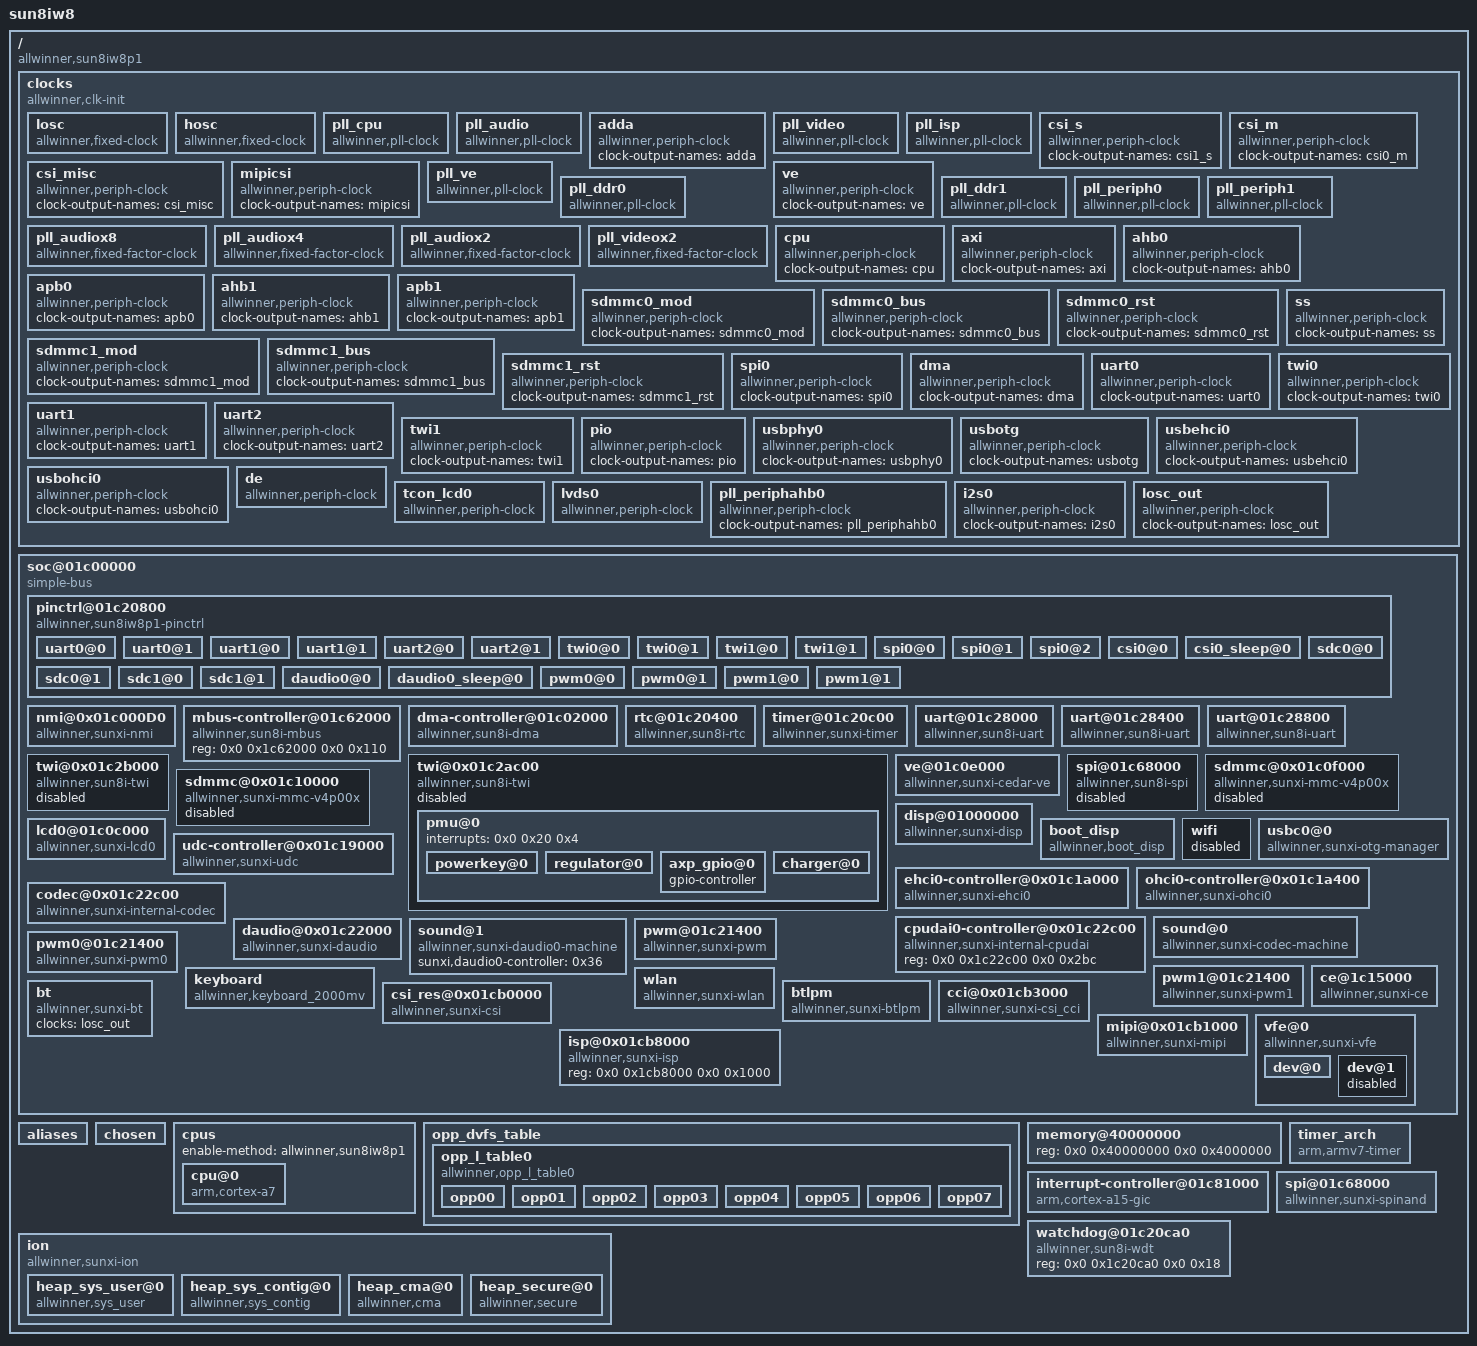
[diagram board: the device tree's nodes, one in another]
/dts-v1/;

/ {
	model = "sun8iw8";
	compatible = "allwinner,sun8iw8p1";
	interrupt-parent = <0x1>;
	#address-cells = <0x2>;
	#size-cells = <0x2>;

	clocks {
		compatible = "allwinner,clk-init";
		device_type = "clocks";
		#address-cells = <0x2>;
		#size-cells = <0x2>;
		ranges;
		reg = <0x0 0x1c20000 0x0 0x324 0x0 0x1c20460 0x0 0x4>;

		losc {
			#clock-cells = <0x0>;
			compatible = "allwinner,fixed-clock";
			clock-frequency = <0x8000>;
			clock-output-names = "losc";
		};

		hosc {
			#clock-cells = <0x0>;
			compatible = "allwinner,fixed-clock";
			clock-frequency = <0x16e3600>;
			clock-output-names = "hosc";
			linux,phandle = <0x1f>;
			phandle = <0x1f>;
		};

		pll_cpu {
			#clock-cells = <0x0>;
			compatible = "allwinner,pll-clock";
			lock-mode = "old";
			assigned-clock-rates = <0x1f78a400>;
			clock-output-names = "pll_cpu";
			linux,phandle = <0x43>;
			phandle = <0x43>;
		};

		pll_audio {
			#clock-cells = <0x0>;
			compatible = "allwinner,pll-clock";
			lock-mode = "old";
			clock-output-names = "pll_audio";
			linux,phandle = <0x2>;
			phandle = <0x2>;
		};

		adda {
			#clock-cells = <0x0>;
			compatible = "allwinner,periph-clock";
			clock-output-names = "adda";
			linux,phandle = <0x30>;
			phandle = <0x30>;
		};

		pll_video {
			#clock-cells = <0x0>;
			compatible = "allwinner,pll-clock";
			lock-mode = "old";
			assigned-clock-rates = <0x11b3dc40>;
			clock-output-names = "pll_video";
			linux,phandle = <0x3>;
			phandle = <0x3>;
		};

		pll_isp {
			#clock-cells = <0x0>;
			compatible = "allwinner,pll-clock";
			lock-mode = "old";
			clock-output-names = "pll_isp";
			linux,phandle = <0x41>;
			phandle = <0x41>;
		};

		csi_s {
			#clock-cells = <0x0>;
			compatible = "allwinner,periph-clock";
			clock-output-names = "csi1_s";
			linux,phandle = <0x3e>;
			phandle = <0x3e>;
		};

		csi_m {
			#clock-cells = <0x0>;
			compatible = "allwinner,periph-clock";
			clock-output-names = "csi0_m";
			linux,phandle = <0x3f>;
			phandle = <0x3f>;
		};

		csi_misc {
			#clock-cells = <0x0>;
			compatible = "allwinner,periph-clock";
			clock-output-names = "csi_misc";
			linux,phandle = <0x40>;
			phandle = <0x40>;
		};

		mipicsi {
			#clock-cells = <0x0>;
			compatible = "allwinner,periph-clock";
			clock-output-names = "mipicsi";
			linux,phandle = <0x42>;
			phandle = <0x42>;
		};

		pll_ve {
			#clock-cells = <0x0>;
			compatible = "allwinner,pll-clock";
			lock-mode = "old";
			clock-output-names = "pll_ve";
			linux,phandle = <0x19>;
			phandle = <0x19>;
		};

		ve {
			#clock-cells = <0x0>;
			compatible = "allwinner,periph-clock";
			clock-output-names = "ve";
			linux,phandle = <0x1a>;
			phandle = <0x1a>;
		};

		pll_ddr0 {
			#clock-cells = <0x0>;
			compatible = "allwinner,pll-clock";
			lock-mode = "old";
			assigned-clock-rates = <0x1298be00>;
			clock-output-names = "pll_ddr0";
		};

		pll_ddr1 {
			#clock-cells = <0x0>;
			compatible = "allwinner,pll-clock";
			lock-mode = "old";
			clock-output-names = "pll_ddr1";
		};

		pll_periph0 {
			#clock-cells = <0x0>;
			compatible = "allwinner,pll-clock";
			lock-mode = "old";
			clock-output-names = "pll_periph0";
			linux,phandle = <0x4>;
			phandle = <0x4>;
		};

		pll_periph1 {
			#clock-cells = <0x0>;
			compatible = "allwinner,pll-clock";
			lock-mode = "old";
			clock-output-names = "pll_periph1";
			linux,phandle = <0x20>;
			phandle = <0x20>;
		};

		pll_audiox8 {
			#clock-cells = <0x0>;
			compatible = "allwinner,fixed-factor-clock";
			clocks = <0x2>;
			clock-mult = <0x8>;
			clock-div = <0x1>;
			clock-output-names = "pll_audiox8";
		};

		pll_audiox4 {
			#clock-cells = <0x0>;
			compatible = "allwinner,fixed-factor-clock";
			clocks = <0x2>;
			clock-mult = <0x8>;
			clock-div = <0x2>;
			clock-output-names = "pll_audiox4";
		};

		pll_audiox2 {
			#clock-cells = <0x0>;
			compatible = "allwinner,fixed-factor-clock";
			clocks = <0x2>;
			clock-mult = <0x8>;
			clock-div = <0x4>;
			clock-output-names = "pll_audiox2";
		};

		pll_videox2 {
			#clock-cells = <0x0>;
			compatible = "allwinner,fixed-factor-clock";
			clocks = <0x3>;
			clock-mult = <0x2>;
			clock-div = <0x1>;
			clock-output-names = "pll_videox2";
		};

		cpu {
			#clock-cells = <0x0>;
			compatible = "allwinner,periph-clock";
			clock-output-names = "cpu";
		};

		axi {
			#clock-cells = <0x0>;
			compatible = "allwinner,periph-clock";
			clock-output-names = "axi";
		};

		ahb0 {
			#clock-cells = <0x0>;
			compatible = "allwinner,periph-clock";
			clock-output-names = "ahb0";
		};

		apb0 {
			#clock-cells = <0x0>;
			compatible = "allwinner,periph-clock";
			clock-output-names = "apb0";
		};

		ahb1 {
			#clock-cells = <0x0>;
			compatible = "allwinner,periph-clock";
			clock-output-names = "ahb1";
		};

		apb1 {
			#clock-cells = <0x0>;
			compatible = "allwinner,periph-clock";
			clock-output-names = "apb1";
		};

		sdmmc0_mod {
			#clock-cells = <0x0>;
			compatible = "allwinner,periph-clock";
			clock-output-names = "sdmmc0_mod";
			linux,phandle = <0x21>;
			phandle = <0x21>;
		};

		sdmmc0_bus {
			#clock-cells = <0x0>;
			compatible = "allwinner,periph-clock";
			clock-output-names = "sdmmc0_bus";
			linux,phandle = <0x22>;
			phandle = <0x22>;
		};

		sdmmc0_rst {
			#clock-cells = <0x0>;
			compatible = "allwinner,periph-clock";
			clock-output-names = "sdmmc0_rst";
			linux,phandle = <0x23>;
			phandle = <0x23>;
		};

		sdmmc1_mod {
			#clock-cells = <0x0>;
			compatible = "allwinner,periph-clock";
			clock-output-names = "sdmmc1_mod";
			linux,phandle = <0x27>;
			phandle = <0x27>;
		};

		sdmmc1_bus {
			#clock-cells = <0x0>;
			compatible = "allwinner,periph-clock";
			clock-output-names = "sdmmc1_bus";
			linux,phandle = <0x28>;
			phandle = <0x28>;
		};

		sdmmc1_rst {
			#clock-cells = <0x0>;
			compatible = "allwinner,periph-clock";
			clock-output-names = "sdmmc1_rst";
			linux,phandle = <0x29>;
			phandle = <0x29>;
		};

		ss {
			#clock-cells = <0x0>;
			compatible = "allwinner,periph-clock";
			clock-output-names = "ss";
			linux,phandle = <0x3d>;
			phandle = <0x3d>;
		};

		spi0 {
			#clock-cells = <0x0>;
			compatible = "allwinner,periph-clock";
			clock-output-names = "spi0";
			linux,phandle = <0x1b>;
			phandle = <0x1b>;
		};

		dma {
			#clock-cells = <0x0>;
			compatible = "allwinner,periph-clock";
			clock-output-names = "dma";
			linux,phandle = <0x9>;
			phandle = <0x9>;
		};

		uart0 {
			#clock-cells = <0x0>;
			compatible = "allwinner,periph-clock";
			clock-output-names = "uart0";
			linux,phandle = <0xa>;
			phandle = <0xa>;
		};

		uart1 {
			#clock-cells = <0x0>;
			compatible = "allwinner,periph-clock";
			clock-output-names = "uart1";
			linux,phandle = <0xd>;
			phandle = <0xd>;
		};

		uart2 {
			#clock-cells = <0x0>;
			compatible = "allwinner,periph-clock";
			clock-output-names = "uart2";
			linux,phandle = <0x10>;
			phandle = <0x10>;
		};

		twi0 {
			#clock-cells = <0x0>;
			compatible = "allwinner,periph-clock";
			clock-output-names = "twi0";
			linux,phandle = <0x13>;
			phandle = <0x13>;
		};

		twi1 {
			#clock-cells = <0x0>;
			compatible = "allwinner,periph-clock";
			clock-output-names = "twi1";
			linux,phandle = <0x16>;
			phandle = <0x16>;
		};

		pio {
			#clock-cells = <0x0>;
			compatible = "allwinner,periph-clock";
			clock-output-names = "pio";
			linux,phandle = <0x8>;
			phandle = <0x8>;
		};

		usbphy0 {
			#clock-cells = <0x0>;
			compatible = "allwinner,periph-clock";
			clock-output-names = "usbphy0";
			linux,phandle = <0x2c>;
			phandle = <0x2c>;
		};

		usbotg {
			#clock-cells = <0x0>;
			compatible = "allwinner,periph-clock";
			clock-output-names = "usbotg";
			linux,phandle = <0x2d>;
			phandle = <0x2d>;
		};

		usbehci0 {
			#clock-cells = <0x0>;
			compatible = "allwinner,periph-clock";
			clock-output-names = "usbehci0";
			linux,phandle = <0x2e>;
			phandle = <0x2e>;
		};

		usbohci0 {
			#clock-cells = <0x0>;
			compatible = "allwinner,periph-clock";
			clock-output-names = "usbohci0";
			linux,phandle = <0x2f>;
			phandle = <0x2f>;
		};

		de {
			#clock-cells = <0x0>;
			compatible = "allwinner,periph-clock";
			assigned-clock-parents = <0x4>;
			assigned-clock-rates = <0x11e1a300>;
			assigned-clocks = <0x5>;
			clock-output-names = "de";
			linux,phandle = <0x5>;
			phandle = <0x5>;
		};

		tcon_lcd0 {
			#clock-cells = <0x0>;
			compatible = "allwinner,periph-clock";
			assigned-clocks = <0x6>;
			clock-output-names = "tcon";
			linux,phandle = <0x6>;
			phandle = <0x6>;
		};

		lvds0 {
			#clock-cells = <0x0>;
			compatible = "allwinner,periph-clock";
			assigned-clocks = <0x7>;
			clock-output-names = "lvds";
			linux,phandle = <0x7>;
			phandle = <0x7>;
		};

		pll_periphahb0 {
			#clock-cells = <0x0>;
			compatible = "allwinner,periph-clock";
			clock-output-names = "pll_periphahb0";
		};

		i2s0 {
			#clock-cells = <0x0>;
			compatible = "allwinner,periph-clock";
			clock-output-names = "i2s0";
			linux,phandle = <0x33>;
			phandle = <0x33>;
		};

		losc_out {
			#clock-cells = <0x0>;
			compatible = "allwinner,periph-clock";
			clock-output-names = "losc_out";
		};
	};

	soc@01c00000 {
		compatible = "simple-bus";
		#address-cells = <0x2>;
		#size-cells = <0x2>;
		device_type = "soc";
		ranges;

		pinctrl@01c20800 {
			compatible = "allwinner,sun8iw8p1-pinctrl";
			reg = <0x0 0x1c20800 0x0 0x400>;
			device_type = "pio";
			clocks = <0x8>;
			gpio-controller;
			interrupt-controller;
			#interrupt-cells = <0x2>;
			#size-cells = <0x0>;
			#gpio-cells = <0x6>;
			interrupts = <0x0 0xf 0x4 0x0 0x11 0x4>;
			linux,phandle = <0x26>;
			phandle = <0x26>;

			uart0@0 {
				allwinner,pins = "PB8", "PB9";
				allwinner,pname = "uart0_tx", "uart0_rx";
				allwinner,function = "uart0";
				allwinner,muxsel = <0x3>;
				allwinner,drive = <0x1>;
				allwinner,pull = <0x1>;
				linux,phandle = <0xb>;
				phandle = <0xb>;
			};

			uart0@1 {
				allwinner,pins = "PB8", "PB9";
				allwinner,function = "io_disabled";
				allwinner,muxsel = <0x7>;
				allwinner,drive = <0x1>;
				allwinner,pull = <0x1>;
				linux,phandle = <0xc>;
				phandle = <0xc>;
			};

			uart1@0 {
				allwinner,pins = "PE21", "PE22";
				allwinner,pname = "uart1_tx", "uart1_rx";
				allwinner,function = "uart1";
				allwinner,muxsel = <0x4>;
				allwinner,drive = <0x1>;
				allwinner,pull = <0x1>;
				linux,phandle = <0xe>;
				phandle = <0xe>;
			};

			uart1@1 {
				allwinner,pins = "PE21", "PE22";
				allwinner,function = "io_disabled";
				allwinner,muxsel = <0x7>;
				allwinner,drive = <0x1>;
				allwinner,pull = <0x1>;
				linux,phandle = <0xf>;
				phandle = <0xf>;
			};

			uart2@0 {
				allwinner,pins = "PB0", "PB1";
				allwinner,pname = "uart2_tx", "uart2_rx";
				allwinner,function = "uart2";
				allwinner,muxsel = <0x2>;
				allwinner,drive = <0x1>;
				allwinner,pull = <0x1>;
				linux,phandle = <0x11>;
				phandle = <0x11>;
			};

			uart2@1 {
				allwinner,pins = "PB0", "PB1";
				allwinner,function = "io_disabled";
				allwinner,muxsel = <0x7>;
				allwinner,drive = <0x1>;
				allwinner,pull = <0x1>;
				linux,phandle = <0x12>;
				phandle = <0x12>;
			};

			twi0@0 {
				allwinner,pins = "PB6", "PB7";
				allwinner,pname = "twi0_scl", "twi0_sda";
				allwinner,function = "twi0";
				allwinner,muxsel = <0x2>;
				allwinner,drive = <0x1>;
				allwinner,pull = <0x0>;
				linux,phandle = <0x14>;
				phandle = <0x14>;
			};

			twi0@1 {
				allwinner,pins = "PB6", "PB7";
				allwinner,function = "io_disabled";
				allwinner,muxsel = <0x7>;
				allwinner,drive = <0x1>;
				allwinner,pull = <0x0>;
				linux,phandle = <0x15>;
				phandle = <0x15>;
			};

			twi1@0 {
				allwinner,pins = "PB8", "PB9";
				allwinner,pname = "twi1_scl", "twi1_sda";
				allwinner,function = "twi1";
				allwinner,muxsel = <0x2>;
				allwinner,drive = <0x1>;
				allwinner,pull = <0x0>;
				linux,phandle = <0x17>;
				phandle = <0x17>;
			};

			twi1@1 {
				allwinner,pins = "PB8", "PB9";
				allwinner,function = "io_disabled";
				allwinner,muxsel = <0x7>;
				allwinner,drive = <0x1>;
				allwinner,pull = <0x0>;
				linux,phandle = <0x18>;
				phandle = <0x18>;
			};

			spi0@0 {
				allwinner,pins = "PC3", "PC0", "PC1";
				allwinner,pname = "spi0_mosi", "spi0_miso", "spi0_sclk";
				allwinner,function = "spi0";
				allwinner,muxsel = <0x3>;
				allwinner,drive = <0x1>;
				allwinner,pull = <0x0>;
				linux,phandle = <0x1c>;
				phandle = <0x1c>;
			};

			spi0@1 {
				allwinner,pins = "PC2";
				allwinner,pname = "spi0_cs0";
				allwinner,function = "spi0";
				allwinner,muxsel = <0x3>;
				allwinner,drive = <0x1>;
				allwinner,pull = <0x1>;
				linux,phandle = <0x1d>;
				phandle = <0x1d>;
			};

			spi0@2 {
				allwinner,pins = "PC3", "PC0", "PC1", "PC2";
				allwinner,function = "io_disabled";
				allwinner,muxsel = <0x7>;
				allwinner,drive = <0x3>;
				allwinner,pull = <0x1>;
				linux,phandle = <0x1e>;
				phandle = <0x1e>;
			};

			csi0@0 {
				allwinner,pins = "PE21", "PE22";
				allwinner,pname = "csi0_sck", "csi0_sda";
				allwinner,function = "csi0";
				allwinner,muxsel = <0x3>;
				allwinner,drive = <0x1>;
				allwinner,pull = <0x0>;
			};

			csi0_sleep@0 {
				allwinner,pins = "PE21", "PE22";
				allwinner,pname = "csi0_sck", "csi0_sda";
				allwinner,function = "io_disabled";
				allwinner,muxsel = <0x7>;
				allwinner,drive = <0x1>;
				allwinner,pull = <0x0>;
			};

			sdc0@0 {
				allwinner,pins = "PF0", "PF1", "PF2", "PF3", "PF4", "PF5";
				allwinner,function = "sdc0";
				allwinner,muxsel = <0x2>;
				allwinner,drive = <0x1>;
				allwinner,pull = <0x1>;
				linux,phandle = <0x24>;
				phandle = <0x24>;
			};

			sdc0@1 {
				allwinner,pins = "PF0", "PF1", "PF2", "PF3", "PF4", "PF5";
				allwinner,function = "io_disabled";
				allwinner,muxsel = <0x7>;
				allwinner,drive = <0x1>;
				allwinner,pull = <0x1>;
				linux,phandle = <0x25>;
				phandle = <0x25>;
			};

			sdc1@0 {
				allwinner,pins = "PG0", "PG1", "PG2", "PG3", "PG4", "PG5";
				allwinner,function = "sdc1";
				allwinner,muxsel = <0x2>;
				allwinner,drive = <0x1>;
				allwinner,pull = <0x1>;
				linux,phandle = <0x2a>;
				phandle = <0x2a>;
			};

			sdc1@1 {
				allwinner,pins = "PG0", "PG1", "PG2", "PG3", "PG4", "PG5";
				allwinner,function = "io_disabled";
				allwinner,muxsel = <0x7>;
				allwinner,drive = <0x1>;
				allwinner,pull = <0x1>;
				linux,phandle = <0x2b>;
				phandle = <0x2b>;
			};

			daudio0@0 {
				allwinner,pins = "PG10", "PG11", "PG12";
				allwinner,function = "tdm0";
				allwinner,muxsel = <0x2>;
				allwinner,driver = <0x1>;
				allwinner,pull = <0x1>;
				linux,phandle = <0x34>;
				phandle = <0x34>;
			};

			daudio0_sleep@0 {
				allwinner,pins = "PG10", "PG11", "PG12";
				allwinner,function = "io_disable";
				allwinner,muxsel = <0x7>;
				allwinner,driver = <0x1>;
				allwinner,pull = <0x1>;
				linux,phandle = <0x35>;
				phandle = <0x35>;
			};

			pwm0@0 {
				allwinner,pins = "PB4";
				allwinner,function = "pwm0";
				allwinner,muxsel = <0x2>;
				allwinner,drive = <0x1>;
				allwinner,pull = <0x1>;
				linux,phandle = <0x39>;
				phandle = <0x39>;
			};

			pwm0@1 {
				allwinner,pins = "PB4";
				allwinner,function = "io_disabled";
				allwinner,muxsel = <0x7>;
				allwinner,drive = <0x1>;
				allwinner,pull = <0x1>;
				linux,phandle = <0x3a>;
				phandle = <0x3a>;
			};

			pwm1@0 {
				allwinner,pins = "PB5";
				allwinner,function = "pwm1";
				allwinner,muxsel = <0x2>;
				allwinner,drive = <0x1>;
				allwinner,pull = <0x1>;
				linux,phandle = <0x3b>;
				phandle = <0x3b>;
			};

			pwm1@1 {
				allwinner,pins = "PB5";
				allwinner,function = "io_disabled";
				allwinner,muxsel = <0x7>;
				allwinner,drive = <0x1>;
				allwinner,pull = <0x1>;
				linux,phandle = <0x3c>;
				phandle = <0x3c>;
			};
		};

		nmi@0x01c000D0 {
			#address-cells = <0x1>;
			#size-cells = <0x0>;
			compatible = "allwinner,sunxi-nmi";
			reg = <0x0 0x1c000d0 0x0 0x10>;
			nmi_irq_ctrl = <0x0>;
			nmi_irq_en = <0x4>;
			nmi_irq_status = <0x8>;
			status = "okay";
		};

		mbus-controller@01c62000 {
			compatible = "allwinner,sun8i-mbus";
			reg = <0x0 0x1c62000 0x0 0x110>;
			#mbus-cells = <0x1>;
		};

		dma-controller@01c02000 {
			compatible = "allwinner,sun8i-dma";
			reg = <0x0 0x1c02000 0x0 0x1000>;
			interrupts = <0x0 0x32 0x4>;
			clocks = <0x9>;
			#dma-cells = <0x1>;
		};

		rtc@01c20400 {
			compatible = "allwinner,sun8i-rtc";
			device_type = "rtc";
			reg = <0x0 0x1c20400 0x0 0x1f0>;
			interrupts = <0x0 0x28 0x4>;
			gpr_offset = <0x100>;
			gpr_len = <0x4>;
		};

		timer@01c20c00 {
			compatible = "allwinner,sunxi-timer";
			device_type = "timer";
			reg = <0x0 0x1c20c00 0x0 0x400>;
			clock-frequency = <0x16e3600>;
			timer-prescale = <0x10>;
			interrupts = <0x0 0x12 0x1>;
		};

		uart@01c28000 {
			compatible = "allwinner,sun8i-uart";
			device_type = "uart0";
			reg = <0x0 0x1c28000 0x0 0x400>;
			interrupts = <0x0 0x0 0x4>;
			clocks = <0xa>;
			pinctrl-names = "default", "sleep";
			pinctrl-0 = <0xb>;
			pinctrl-1 = <0xc>;
			uart0_port = <0x0>;
			uart0_type = <0x2>;
			status = "okay";
		};

		uart@01c28400 {
			compatible = "allwinner,sun8i-uart";
			device_type = "uart1";
			reg = <0x0 0x1c28400 0x0 0x400>;
			interrupts = <0x0 0x1 0x4>;
			clocks = <0xd>;
			pinctrl-names = "default", "sleep";
			pinctrl-0 = <0xe>;
			pinctrl-1 = <0xf>;
			uart1_port = <0x1>;
			uart1_type = <0x2>;
			status = "okay";
		};

		uart@01c28800 {
			compatible = "allwinner,sun8i-uart";
			device_type = "uart2";
			reg = <0x0 0x1c28800 0x0 0x400>;
			interrupts = <0x0 0x2 0x4>;
			clocks = <0x10>;
			pinctrl-names = "default", "sleep";
			pinctrl-0 = <0x11>;
			pinctrl-1 = <0x12>;
			uart2_port = <0x2>;
			uart2_type = <0x2>;
			status = "okay";
		};

		twi@0x01c2ac00 {
			#address-cells = <0x1>;
			#size-cells = <0x0>;
			compatible = "allwinner,sun8i-twi";
			device_type = "twi0";
			reg = <0x0 0x1c2ac00 0x0 0x400>;
			interrupts = <0x0 0x6 0x4>;
			clocks = <0x13>;
			clock-frequency = <0x61a80>;
			pinctrl-names = "default", "sleep";
			pinctrl-0 = <0x14>;
			pinctrl-1 = <0x15>;
			status = "disabled";

			pmu@0 {
				#address-cells = <0x1>;
				#size-cells = <0x0>;
				interrupts = <0x0 0x20 0x4>;
				status = "okay";

				powerkey@0 {
					status = "okay";
				};

				regulator@0 {
					status = "okay";
				};

				axp_gpio@0 {
					gpio-controller;
					#size-cells = <0x0>;
					#gpio-cells = <0x6>;
					status = "okay";
				};

				charger@0 {
					status = "okay";
				};
			};
		};

		twi@0x01c2b000 {
			#address-cells = <0x1>;
			#size-cells = <0x0>;
			compatible = "allwinner,sun8i-twi";
			device_type = "twi1";
			reg = <0x0 0x1c2b000 0x0 0x400>;
			interrupts = <0x0 0x7 0x4>;
			clocks = <0x16>;
			clock-frequency = <0x30d40>;
			pinctrl-names = "default", "sleep";
			pinctrl-0 = <0x17>;
			pinctrl-1 = <0x18>;
			status = "disabled";
		};

		ve@01c0e000 {
			compatible = "allwinner,sunxi-cedar-ve";
			reg = <0x0 0x1c0e000 0x0 0x1000 0x0 0x1c00000 0x0 0x10 0x0 0x1c20000 0x0 0x1000>;
			interrupts = <0x0 0x3a 0x4>;
			clocks = <0x19 0x1a>;
		};

		spi@01c68000 {
			#address-cells = <0x1>;
			#size-cells = <0x0>;
			compatible = "allwinner,sun8i-spi";
			device_type = "spi0";
			reg = <0x0 0x1c68000 0x0 0x1000>;
			interrupts = <0x0 0x41 0x4>;
			clocks = <0x4 0x1b>;
			clock-frequency = <0x5f5e100>;
			pinctrl-names = "default", "sleep";
			pinctrl-0 = <0x1c 0x1d>;
			pinctrl-1 = <0x1e>;
			spi0_cs_number = <0x1>;
			spi0_cs_bitmap = <0x1>;
			status = "disabled";
		};

		sdmmc@0x01c0f000 {
			compatible = "allwinner,sunxi-mmc-v4p00x";
			device_type = "sdc0";
			reg = <0x0 0x1c0f000 0x0 0x1000>;
			interrupts = <0x0 0x3c 0x104>;
			clocks = <0x1f 0x20 0x21 0x22 0x23>;
			clock-names = "osc24m", "pll_periph", "mmc", "ahb", "rst";
			pinctrl-names = "default", "sleep";
			pinctrl-0 = <0x24>;
			pinctrl-1 = <0x25>;
			max-frequency = <0x2faf080>;
			bus-width = <0x4>;
			cd-gpios = <0x26 0x5 0x6 0x0 0x1 0x2 0x0>;
			status = "disabled";
		};

		sdmmc@0x01c10000 {
			compatible = "allwinner,sunxi-mmc-v4p00x";
			device_type = "sdc1";
			reg = <0x0 0x1c10000 0x0 0x1000>;
			interrupts = <0x0 0x3d 0x104>;
			clocks = <0x1f 0x20 0x27 0x28 0x29>;
			clock-names = "osc24m", "pll_periph", "mmc", "ahb", "rst";
			pinctrl-names = "default", "sleep";
			pinctrl-0 = <0x2a>;
			pinctrl-1 = <0x2b>;
			max-frequency = <0x2faf080>;
			bus-width = <0x4>;
			status = "disabled";
		};

		disp@01000000 {
			compatible = "allwinner,sunxi-disp";
			reg = <0x0 0x1000000 0x0 0x200000 0x0 0x1c0c000 0x0 0x1000>;
			interrupts = <0x0 0x56 0x104 0x0 0x5f 0x104>;
			clocks = <0x5 0x6 0x7>;
			boot_disp = <0x0>;
			fb_base = <0x0>;
			dma-coherent;
			status = "okay";
		};

		lcd0@01c0c000 {
			compatible = "allwinner,sunxi-lcd0";
			pinctrl-names = "active", "sleep";
			status = "okay";
		};

		boot_disp {
			compatible = "allwinner,boot_disp";
		};

		wifi {
			device_type = "wifi_conf";
			interrupts = <0x0 0x6b 0x0>;
			reset_pin = <0x26 0x4 0x17 0x1 0x1 0x1 0x0>;
			irq_pin = <0x26 0x1 0x5 0x6 0x1 0x1 0x0>;
			status = "disabled";
		};

		usbc0@0 {
			device_type = "usbc0";
			compatible = "allwinner,sunxi-otg-manager";
			usb_port_type = <0x0>;
			usb_detect_type = <0x1>;
			usb_host_init_state = <0x0>;
			usb_regulator_io = "nocare";
			usb_wakeup_suspend = <0x0>;
			usb_luns = <0x1>;
			usb_serial_unique = <0x0>;
			usb_serial_number = "20080411";
			rndis_wceis = <0x1>;
			status = "okay";
		};

		udc-controller@0x01c19000 {
			compatible = "allwinner,sunxi-udc";
			reg = <0x0 0x1c19000 0x0 0x1000 0x0 0x1c00000 0x0 0x100>;
			interrupts = <0x0 0x47 0x4>;
			clocks = <0x2c 0x2d>;
			status = "okay";
		};

		ehci0-controller@0x01c1a000 {
			compatible = "allwinner,sunxi-ehci0";
			reg = <0x0 0x1c1a000 0x0 0xfff 0x0 0x1c00000 0x0 0x100 0x0 0x1c19000 0x0 0x1000>;
			interrupts = <0x0 0x48 0x4>;
			clocks = <0x2c 0x2e>;
			hci_ctrl_no = <0x0>;
			status = "okay";
		};

		ohci0-controller@0x01c1a400 {
			compatible = "allwinner,sunxi-ohci0";
			reg = <0x0 0x1c1a000 0x0 0xfff 0x0 0x1c00000 0x0 0x100 0x0 0x1c19000 0x0 0x1000>;
			interrupts = <0x0 0x49 0x4>;
			clocks = <0x2c 0x2f>;
			hci_ctrl_no = <0x0>;
			status = "okay";
		};

		codec@0x01c22c00 {
			compatible = "allwinner,sunxi-internal-codec";
			reg = <0x0 0x1c22c00 0x0 0x2bc 0x0 0x1c23000 0x0 0x4>;
			clocks = <0x2 0x30>;
			headphone_vol = <0x3b>;
			spker_vol = <0x1b>;
			audio_pa_ctrl = <0x26 0x1 0x9 0x1 0x1 0x1 0x1>;
			main_mic_vol = <0x4>;
			hp_dirused = <0x1>;
			headset_mic_vol = <0x4>;
			pa_sleep_time = <0x15e>;
			status = "okay";
			linux,phandle = <0x32>;
			phandle = <0x32>;
		};

		cpudai0-controller@0x01c22c00 {
			compatible = "allwinner,sunxi-internal-cpudai";
			reg = <0x0 0x1c22c00 0x0 0x2bc>;
			status = "okay";
			linux,phandle = <0x31>;
			phandle = <0x31>;
		};

		sound@0 {
			compatible = "allwinner,sunxi-codec-machine";
			sunxi,cpudai-controller = <0x31>;
			sunxi,audio-codec = <0x32>;
			status = "okay";
		};

		daudio@0x01c22000 {
			compatible = "allwinner,sunxi-daudio";
			reg = <0x0 0x1c22000 0x0 0x58>;
			clocks = <0x2 0x33>;
			pinctrl-names = "default", "sleep";
			pinctrl-0 = <0x34>;
			pinctrl-1 = <0x35>;
			pcm_lrck_period = <0x20>;
			pcm_lrckr_period = <0x1>;
			slot_width_select = <0x20>;
			pcm_lsb_first = <0x0>;
			tx_data_mode = <0x0>;
			rx_data_mode = <0x0>;
			daudio_master = <0x4>;
			audio_format = <0x1>;
			signal_inversion = <0x1>;
			frametype = <0x0>;
			tdm_config = <0x1>;
			mclk_div = <0x0>;
			tdm_num = <0x0>;
			status = "okay";
			linux,phandle = <0x36>;
			phandle = <0x36>;
		};

		sound@1 {
			compatible = "allwinner,sunxi-daudio0-machine";
			sunxi,daudio0-controller = <0x36>;
			status = "okay";
		};

		pwm@01c21400 {
			compatible = "allwinner,sunxi-pwm";
			reg = <0x0 0x1c21400 0x0 0x3c>;
			pwm-number = <0x2>;
			pwm-base = <0x0>;
			pwms = <0x37 0x38>;
		};

		pwm0@01c21400 {
			compatible = "allwinner,sunxi-pwm0";
			pinctrl-names = "active", "sleep";
			pinctrl-0 = <0x39>;
			pinctrl-1 = <0x3a>;
			reg_base = <0x1c21400>;
			reg_busy_offset = <0x0>;
			reg_busy_shift = <0x1c>;
			reg_enable_offset = <0x0>;
			reg_enable_shift = <0x4>;
			reg_clk_gating_offset = <0x0>;
			reg_clk_gating_shift = <0x6>;
			reg_bypass_offset = <0x0>;
			reg_bypass_shift = <0x9>;
			reg_pulse_start_offset = <0x0>;
			reg_pulse_start_shift = <0x8>;
			reg_mode_offset = <0x0>;
			reg_mode_shift = <0x7>;
			reg_polarity_offset = <0x0>;
			reg_polarity_shift = <0x5>;
			reg_period_offset = <0x4>;
			reg_period_shift = <0x10>;
			reg_period_width = <0x10>;
			reg_active_offset = <0x4>;
			reg_active_shift = <0x0>;
			reg_active_width = <0x10>;
			reg_prescal_offset = <0x0>;
			reg_prescal_shift = <0x0>;
			reg_prescal_width = <0x4>;
			linux,phandle = <0x37>;
			phandle = <0x37>;
		};

		pwm1@01c21400 {
			compatible = "allwinner,sunxi-pwm1";
			pinctrl-names = "active", "sleep";
			pinctrl-0 = <0x3b>;
			pinctrl-1 = <0x3c>;
			reg_base = <0x1c21400>;
			reg_busy_offset = <0x0>;
			reg_busy_shift = <0x1d>;
			reg_enable_offset = <0x0>;
			reg_enable_shift = <0x13>;
			reg_clk_gating_offset = <0x0>;
			reg_clk_gating_shift = <0x15>;
			reg_bypass_offset = <0x0>;
			reg_bypass_shift = <0x18>;
			reg_pulse_start_offset = <0x0>;
			reg_pulse_start_shift = <0x17>;
			reg_mode_offset = <0x0>;
			reg_mode_shift = <0x16>;
			reg_polarity_offset = <0x0>;
			reg_polarity_shift = <0x14>;
			reg_period_offset = <0x8>;
			reg_period_shift = <0x10>;
			reg_period_width = <0x10>;
			reg_active_offset = <0x8>;
			reg_active_shift = <0x0>;
			reg_active_width = <0x10>;
			reg_prescal_offset = <0x0>;
			reg_prescal_shift = <0xf>;
			reg_prescal_width = <0x4>;
			linux,phandle = <0x38>;
			phandle = <0x38>;
		};

		keyboard {
			compatible = "allwinner,keyboard_2000mv";
			reg = <0x0 0x1c22800 0x0 0x400>;
			interrupts = <0x0 0x1e 0x0>;
			status = "okay";
			key_cnt = <0x6>;
			key0 = <0xbe 0x73>;
			key1 = <0x186 0x72>;
			key2 = <0x258 0x77>;
			key3 = <0x320 0x71>;
			key4 = <0x3d4 0x69>;
			key5 = <0x4b0 0x6a>;
		};

		ce@1c15000 {
			compatible = "allwinner,sunxi-ce";
			device_name = "ce";
			reg = <0x0 0x1c15000 0x0 0x210>;
			interrupts = <0x0 0x50 0xff01>;
			clock-frequency = <0xbebc200>;
			clocks = <0x3d 0x4>;
		};

		wlan {
			compatible = "allwinner,sunxi-wlan";
			clocks = "losc_out";
			wlan_busnum = <0x1>;
			status = "okay";
		};

		bt {
			compatible = "allwinner,sunxi-bt";
			clocks = "losc_out";
			status = "okay";
		};

		btlpm {
			compatible = "allwinner,sunxi-btlpm";
			status = "okay";
		};

		cci@0x01cb3000 {
			compatible = "allwinner,sunxi-csi_cci";
			reg = <0x0 0x1cb3000 0x0 0x1000>;
			interrupts = <0x0 0x55 0x4>;
			status = "okay";
		};

		csi_res@0x01cb0000 {
			compatible = "allwinner,sunxi-csi";
			reg = <0x0 0x1cb0000 0x0 0x1000>;
			clocks = <0x3e 0x3f 0x40 0x41 0x1f 0x20>;
			clocks-index = <0x0 0x1 0x2 0x3 0x4 0x5>;
			status = "okay";
		};

		mipi@0x01cb1000 {
			compatible = "allwinner,sunxi-mipi";
			reg = <0x0 0x1cb1000 0x0 0x1000>;
			clocks = <0x42 0x42 0x4 0x4>;
			clocks-index = <0xff 0x1 0xff 0x3>;
			status = "okay";
		};

		isp@0x01cb8000 {
			compatible = "allwinner,sunxi-isp";
			reg = <0x0 0x1cb8000 0x0 0x1000>;
			status = "okay";
		};

		vfe@0 {
			device_type = "csi0";
			compatible = "allwinner,sunxi-vfe";
			interrupts = <0x0 0x53 0x4>;
			pinctrl-names = "default", "sleep";
			cci_sel = <0x0>;
			csi_sel = <0x0>;
			mipi_sel = <0x0>;
			isp_sel = <0x0>;
			csi0_sensor_list = <0x0>;
			csi0_mck = <0x26 0x4 0x14 0x3 0x0 0x1 0x0>;
			status = "okay";

			dev@0 {
				csi0_dev0_mname = "hm2131";
				csi0_dev0_twi_id = <0x1>;
				csi0_dev0_twi_addr = <0x48>;
				csi0_dev0_pos = "front";
				csi0_dev0_isp_used = <0x1>;
				csi0_dev0_fmt = <0x1>;
				csi0_dev0_stby_mode = <0x0>;
				csi0_dev0_vflip = <0x0>;
				csi0_dev0_hflip = <0x0>;
				csi0_dev0_iovdd = [00];
				csi0_dev0_iovdd_vol = <0x2ab980>;
				csi0_dev0_avdd = [00];
				csi0_dev0_avdd_vol = <0x2ab980>;
				csi0_dev0_dvdd = [00];
				csi0_dev0_dvdd_vol = <0x16e360>;
				csi0_dev0_afvdd = [00];
				csi0_dev0_afvdd_vol;
				csi0_dev0_power_en;
				csi0_dev0_reset = <0x26 0x4 0x18 0x1 0x0 0x1 0x0>;
				csi0_dev0_pwdn = <0x26 0x4 0x17 0x1 0x0 0x1 0x0>;
				csi0_dev0_flash_used = <0x0>;
				csi0_dev0_flash_type = <0x2>;
				csi0_dev0_flash_en;
				csi0_dev0_flash_mode;
				csi0_dev0_flvdd = [00];
				csi0_dev0_flvdd_vol = <0x325aa0>;
				csi0_dev0_af_pwdn;
				csi0_dev0_act_used = <0x0>;
				csi0_dev0_act_name = "ad5820_act";
				csi0_dev0_act_slave = <0x18>;
				status = "okay";
			};

			dev@1 {
				csi0_dev1_mname = "n3";
				csi0_dev1_twi_addr = <0x60>;
				csi0_dev1_pos = "rear";
				csi0_dev1_isp_used = <0x0>;
				csi0_dev1_fmt = <0x0>;
				csi0_dev1_stby_mode = <0x0>;
				csi0_dev1_vflip = <0x0>;
				csi0_dev1_hflip = <0x0>;
				csi0_dev1_iovdd = "iovdd-csi";
				csi0_dev1_iovdd_vol = <0x2ab980>;
				csi0_dev1_avdd = "avdd-csi";
				csi0_dev1_avdd_vol = <0x2ab980>;
				csi0_dev1_dvdd = "dvdd-csi-18";
				csi0_dev1_dvdd_vol = <0x16e360>;
				csi0_dev1_afvdd = [00];
				csi0_dev1_afvdd_vol;
				csi0_dev1_power_en;
				csi0_dev1_reset;
				csi0_dev1_pwdn;
				csi0_dev1_flash_used = <0x1>;
				csi0_dev1_flash_type = <0x2>;
				csi0_dev1_flash_en;
				csi0_dev1_flash_mode;
				csi0_dev1_flvdd = "vdd-csi-led";
				csi0_dev1_flvdd_vol = <0x325aa0>;
				csi0_dev1_af_pwdn;
				csi0_dev1_act_used = <0x0>;
				csi0_dev1_act_name = "ad5820_act";
				csi0_dev1_act_slave = <0x18>;
				status = "disabled";
			};
		};
	};

	aliases {
		serial0 = "/soc@01c00000/uart@01c28000";
		serial1 = "/soc@01c00000/uart@01c28400";
		serial2 = "/soc@01c00000/uart@01c28800";
		twi0 = "/soc@01c00000/twi@0x01c2ac00";
		twi1 = "/soc@01c00000/twi@0x01c2b000";
		spi0 = "/soc@01c00000/spi@01c68000";
		mmc0 = "/soc@01c00000/sdmmc@0x01c0f000";
		mmc1 = "/soc@01c00000/sdmmc@0x01c10000";
		pwm = "/soc@01c00000/pwm@01c21400";
		pwm0 = "/soc@01c00000/pwm0@01c21400";
		pwm1 = "/soc@01c00000/pwm1@01c21400";
		cci0 = "/soc@01c00000/cci@0x01cb3000";
		csi_res0 = "/soc@01c00000/csi_res@0x01cb0000";
		mipi0 = "/soc@01c00000/mipi@0x01cb1000";
		isp0 = "/soc@01c00000/isp@0x01cb8000";
		vfe0 = "/soc@01c00000/vfe@0";
		global_timer0 = "/soc@01c00000/timer@01c20c00";
		disp = "/soc@01c00000/disp@01000000";
		lcd0 = "/soc@01c00000/lcd0@01c0c000";
		boot_disp = "/soc@01c00000/boot_disp";
		spinand = "/spi@01c68000";
	};

	chosen {
		bootargs = "earlyprintk=sunxi-uart,0x01c28800 loglevel=8 initcall_debug=1 console=ttyS1 init=/init root=/dev/nandd";
		linux,initrd-start = <0x0 0x0>;
		linux,initrd-end = <0x0 0x0>;
	};

	cpus {
		enable-method = "allwinner,sun8iw8p1";
		#address-cells = <0x1>;
		#size-cells = <0x0>;

		cpu@0 {
			device_type = "cpu";
			compatible = "arm,cortex-a7";
			reg = <0x0>;
			enable-method = "psci";
			clocks = <0x43>;
			clock-latency = <0x1e8480>;
			clock-frequency = <0x3c14dc00>;
			operating-points-v2 = <0x44>;
			regulators = "vdd-cpua";
		};
	};

	opp_dvfs_table {
		cluster_num = <0x1>;
		opp_table_count = <0x1>;

		opp_l_table0 {
			compatible = "allwinner,opp_l_table0";
			opp_count = <0x8>;
			opp-shared;
			linux,phandle = <0x44>;
			phandle = <0x44>;

			opp00 {
				opp-hz = <0x0 0x3938700>;
				opp-microvolt = <0x10c8e0>;
				axi-bus-divide-ratio = <0x3>;
				clock-latency-ns = <0x1e8480>;
			};

			opp01 {
				opp-hz = <0x0 0x1c9c3800>;
				opp-microvolt = <0x10c8e0>;
				axi-bus-divide-ratio = <0x3>;
				clock-latency-ns = <0x1e8480>;
			};

			opp02 {
				opp-hz = <0x0 0x269fb200>;
				opp-microvolt = <0x10c8e0>;
				axi-bus-divide-ratio = <0x3>;
				clock-latency-ns = <0x1e8480>;
			};

			opp03 {
				opp-hz = <0x0 0x2aea5400>;
				opp-microvolt = <0x10c8e0>;
				axi-bus-divide-ratio = <0x3>;
				clock-latency-ns = <0x1e8480>;
			};

			opp04 {
				opp-hz = <0x0 0x30a32c00>;
				opp-microvolt = <0x10c8e0>;
				axi-bus-divide-ratio = <0x3>;
				clock-latency-ns = <0x1e8480>;
			};

			opp05 {
				opp-hz = <0x0 0x365c0400>;
				opp-microvolt = <0x124f80>;
				axi-bus-divide-ratio = <0x3>;
				clock-latency-ns = <0x1e8480>;
			};

			opp06 {
				opp-hz = <0x0 0x405f7e00>;
				opp-microvolt = <0x124f80>;
				axi-bus-divide-ratio = <0x3>;
				clock-latency-ns = <0x1e8480>;
			};

			opp07 {
				opp-hz = <0x0 0x47868c00>;
				opp-microvolt = <0x1437c8>;
				axi-bus-divide-ratio = <0x3>;
				clock-latency-ns = <0x1e8480>;
			};
		};
	};

	memory@40000000 {
		device_type = "memory";
		reg = <0x0 0x40000000 0x0 0x4000000>;
	};

	interrupt-controller@01c81000 {
		compatible = "arm,cortex-a15-gic", "arm,cortex-a9-gic";
		#interrupt-cells = <0x3>;
		#address-cells = <0x0>;
		device_type = "gic";
		interrupt-controller;
		reg = <0x0 0x1c81000 0x0 0x1000 0x0 0x1c82000 0x0 0x2000 0x0 0x1c84000 0x0 0x2000 0x0 0x1c86000 0x0 0x2000>;
		interrupts = <0x1 0x9 0xf04>;
		linux,phandle = <0x1>;
		phandle = <0x1>;
	};

	timer_arch {
		compatible = "arm,armv7-timer";
		interrupts = <0x1 0xd 0xf08 0x1 0xe 0xf08 0x1 0xb 0xf08 0x1 0xa 0xf08>;
		clock-frequency = <0x16e3600>;
		arm,cpu-registers-not-fw-configured;
	};

	watchdog@01c20ca0 {
		compatible = "allwinner,sun8i-wdt";
		reg = <0x0 0x1c20ca0 0x0 0x18>;
	};

	ion {
		compatible = "allwinner,sunxi-ion";

		heap_sys_user@0 {
			compatible = "allwinner,sys_user";
			heap-name = "sys_user";
			heap-id = <0x0>;
			heap-base = <0x0>;
			heap-size = <0x0>;
			heap-type = "ion_system";
		};

		heap_sys_contig@0 {
			compatible = "allwinner,sys_contig";
			heap-name = "sys_contig";
			heap-id = <0x1>;
			heap-base = <0x0>;
			heap-size = <0x0>;
			heap-type = "ion_contig";
		};

		heap_cma@0 {
			compatible = "allwinner,cma";
			heap-name = "cma";
			heap-id = <0x4>;
			heap-base = <0x0>;
			heap-size = <0x0>;
			heap-type = "ion_cma";
		};

		heap_secure@0 {
			compatible = "allwinner,secure";
			heap-name = "secure";
			heap-id = <0x6>;
			heap-base = <0x0>;
			heap-size = <0x0>;
			heap-type = "ion_secure";
		};
	};

	spi@01c68000 {
		compatible = "allwinner,sunxi-spinand";
		device_type = "spinand";
		reg = <0x0 0x1c68000 0x0 0x1000>;
		interrupts = <0x0 0x41 0x4>;
		clocks = <0x4 0x1b>;
		pinctrl-names = "default", "sleep";
		pinctrl-0 = <0x1c 0x1d>;
		pinctrl-1 = <0x1e>;
		nand0_regulator1 = "vcc-nand";
		nand0_regulator2 = "none";
		nand0_cache_level = <0x55aaaa55>;
		nand0_flush_cache_num = <0x55aaaa55>;
		nand0_capacity_level = <0x55aaaa55>;
		nand0_id_number_ctl = <0x55aaaa55>;
		nand0_print_level = <0x55aaaa55>;
		nand0_p0 = <0x55aaaa55>;
		nand0_p1 = <0x55aaaa55>;
		nand0_p2 = <0x55aaaa55>;
		nand0_p3 = <0x55aaaa55>;
		status = "okay";
	};
};
